# M0+ register map
Registers are 32-bit, read-write, reset 0x0 unless marked. A register's access mark holds for its fields unless they carry their own. Offsets are from the block's base; lines under a group give offsets from that group; [hi:lo] are bit positions; {n}, {i} and the like mark numbered series; 'fields as' and 'values as' point back to an identical list; <NAME> marks a mode.

## Memory map
0xE000E010 STK size 0x11 — SysTick timer
0xE000E100 NVIC size 0x33D — Nested Vectored Interrupt Controller
0xE000ED00 SCB size 0x41 — System control block
0xE000ED90 MPU size 0x15 — Memory protection unit
0xE000EF34 FPU size 0xD — Floting point unit

## FPU — Floting point unit
Base 0xE000EF34
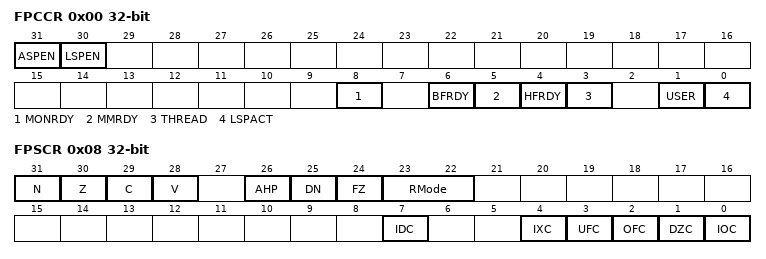
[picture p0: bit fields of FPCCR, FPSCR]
0x00 FPCCR — Floating-point context control register
  [31] ASPEN, [30] LSPEN, [8] MONRDY, [6] BFRDY, [5] MMRDY, [4] HFRDY, [3] THREAD, [1] USER, [0] LSPACT
0x04 FPCAR — Floating-point context address register
  [31:3] ADDRESS — Location of unpopulated floating-point
0x08 FPSCR — Floating-point status control register
  [31] N — Negative condition code flag
  [30] Z — Zero condition code flag
  [29] C — Carry condition code flag
  [28] V — Overflow condition code flag
  [26] AHP — Alternative half-precision control bit
  [25] DN — Default NaN mode control bit
  [24] FZ — Flush-to-zero mode control bit:
  [23:22] RMode — Rounding Mode control field
  [7] IDC — Input denormal cumulative exception bit.
  [4] IXC — Inexact cumulative exception bit
  [3] UFC — Underflow cumulative exception bit
  [2] OFC — Overflow cumulative exception bit
  [1] DZC — Division by zero cumulative exception bit.
  [0] IOC — Invalid operation cumulative exception bit

## MPU — Memory protection unit
Base 0xE000ED90
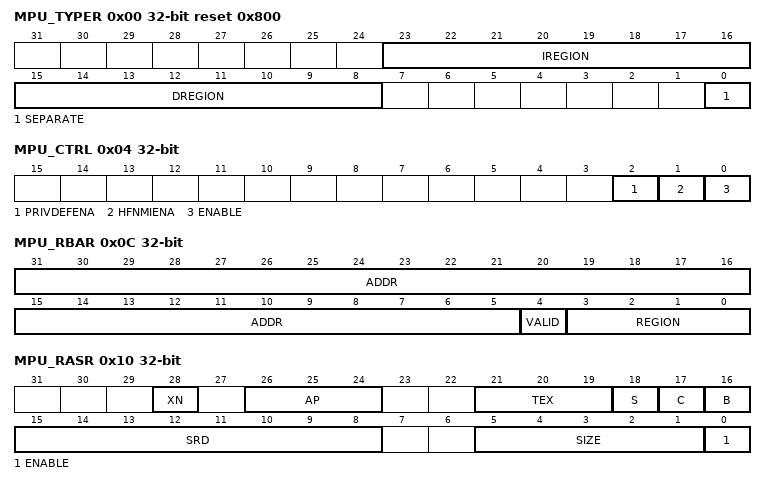
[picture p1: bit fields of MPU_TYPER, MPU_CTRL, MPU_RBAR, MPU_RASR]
0x00 MPU_TYPER ro reset 0x800 — MPU type register
  [23:16] IREGION — Number of MPU instruction regions
  [15:8] DREGION — Number of MPU data regions
  [0] SEPARATE — Separate flag
0x04 MPU_CTRL — MPU control register
  [2] PRIVDEFENA — Enable priviliged software access to default memory map
  [1] HFNMIENA — Enables the operation of MPU during hard fault
  [0] ENABLE — Enables the MPU
0x08 MPU_RNR — MPU region number register
  [7:0] REGION — MPU region
0x0C MPU_RBAR — MPU region base address register
  [31:5] ADDR — Region base address field
  [4] VALID — MPU region number valid
  [3:0] REGION — MPU region field
0x10 MPU_RASR — MPU region attribute and size register
  [28] XN — Instruction access disable bit
  [26:24] AP — Access permission
  [21:19] TEX — memory attribute
  [18] S — Shareable memory attribute
  [17] C — memory attribute
  [16] B — memory attribute
  [15:8] SRD — Subregion disable bits
  [5:1] SIZE — Size of the MPU protection region
  [0] ENABLE — Region enable bit.

## NVIC — Nested Vectored Interrupt Controller
Base 0xE000E100
0x00 ISER — Interrupt Set Enable Register
  [31:0] SETENA
0x80 ICER — Interrupt Clear Enable Register
  [31:0] CLRENA
0x100 ISPR — Interrupt Set-Pending Register
  [31:0] SETPEND
0x180 ICPR — Interrupt Clear-Pending Register
  [31:0] CLRPEND
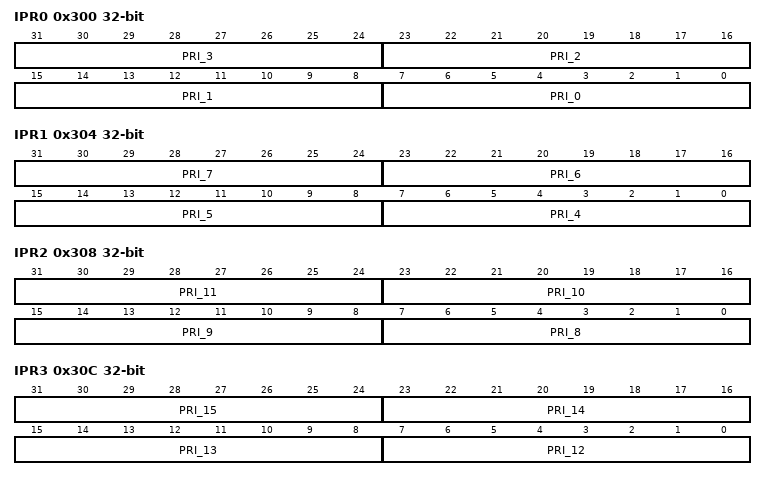
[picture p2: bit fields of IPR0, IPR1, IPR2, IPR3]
0x300 IPR0 — Interrupt Priority Register 0
  [8n+7:8n] PRI_{n} (n=0..3) — priority for interrupt {n}
0x304 IPR1 — Interrupt Priority Register 1
  [8n-25:8n-32] PRI_{n} (n=4..7) — priority for interrupt n
0x308 IPR2 — Interrupt Priority Register 2
  [8n-57:8n-64] PRI_{n} (n=8..11) — priority for interrupt n
0x30C IPR3 — Interrupt Priority Register 3
  [8n-89:8n-96] PRI_{n} (n=12..15) — priority for interrupt n
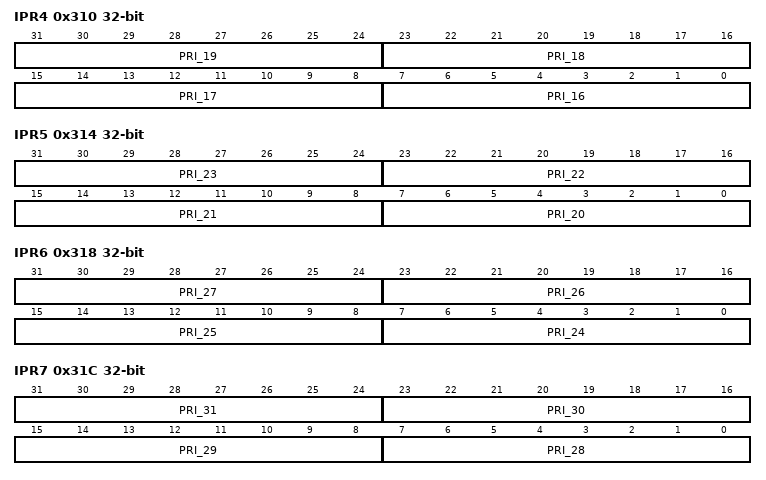
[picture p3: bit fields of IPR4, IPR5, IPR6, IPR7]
0x310 IPR4 — Interrupt Priority Register 4
  [8n-121:8n-128] PRI_{n} (n=16..19) — priority for interrupt n
0x314 IPR5 — Interrupt Priority Register 5
  [8n-153:8n-160] PRI_{n} (n=20..23) — priority for interrupt n
0x318 IPR6 — Interrupt Priority Register 6
  [8n-185:8n-192] PRI_{n} (n=24..27) — priority for interrupt n
0x31C IPR7 — Interrupt Priority Register 7
  [8n-217:8n-224] PRI_{n} (n=28..31) — priority for interrupt n
0x320 IPR8 — Interrupt Priority Register 8

## SCB — System control block
Base 0xE000ED00
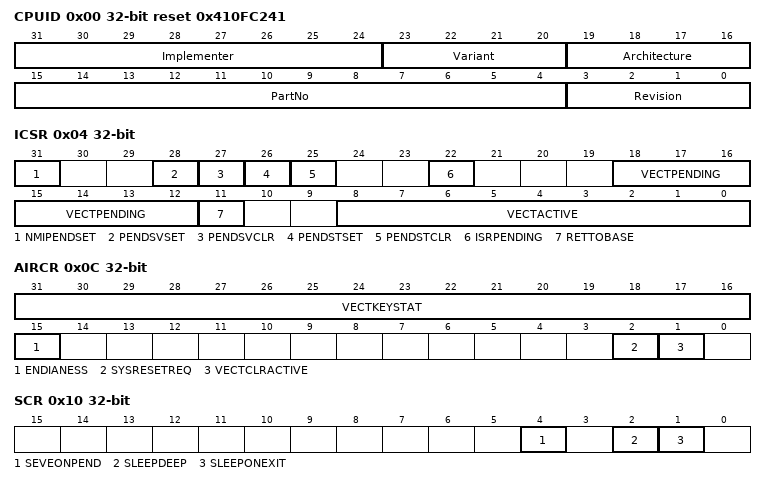
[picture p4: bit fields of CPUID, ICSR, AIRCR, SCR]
0x00 CPUID ro reset 0x410FC241 — CPUID base register
  [31:24] Implementer — Implementer code
  [23:20] Variant — Variant number
  [19:16] Architecture — Reads as 0xF
  [15:4] PartNo — Part number of the processor
  [3:0] Revision — Revision number
0x04 ICSR — Interrupt control and state register
  [31] NMIPENDSET — NMI set-pending bit.
  [28] PENDSVSET — PendSV set-pending bit
  [27] PENDSVCLR — PendSV clear-pending bit
  [26] PENDSTSET — SysTick exception set-pending bit
  [25] PENDSTCLR — SysTick exception clear-pending bit
  [22] ISRPENDING — Interrupt pending flag
  [18:12] VECTPENDING — Pending vector
  [11] RETTOBASE — Return to base level
  [8:0] VECTACTIVE — Active vector
0x08 VTOR — Vector table offset register
  [31:7] TBLOFF — Vector table base offset field
0x0C AIRCR — Application interrupt and reset control register
  [31:16] VECTKEYSTAT — Register key
  [15] ENDIANESS
  [2] SYSRESETREQ
  [1] VECTCLRACTIVE
0x10 SCR — System control register
  [4] SEVEONPEND — Send Event on Pending bit
  [2] SLEEPDEEP
  [1] SLEEPONEXIT
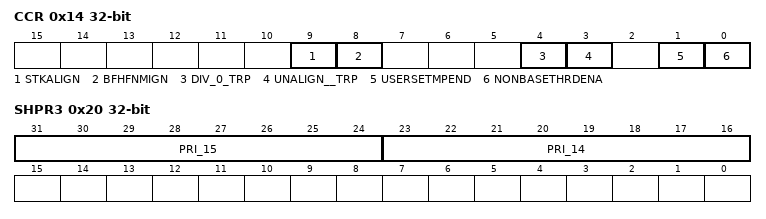
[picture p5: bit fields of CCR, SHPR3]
0x14 CCR — Configuration and control register
  [9] STKALIGN
  [8] BFHFNMIGN
  [4] DIV_0_TRP
  [3] UNALIGN__TRP
  [1] USERSETMPEND
  [0] NONBASETHRDENA — Configures how the processor enters Thread mode
0x1C SHPR2 — System handler priority registers
  [31:24] PRI_11 — Priority of system handler 11
0x20 SHPR3 — System handler priority registers
  [31:24] PRI_15 — Priority of system handler 15
  [23:16] PRI_14 — Priority of system handler 14

## STK — SysTick timer
Base 0xE000E010
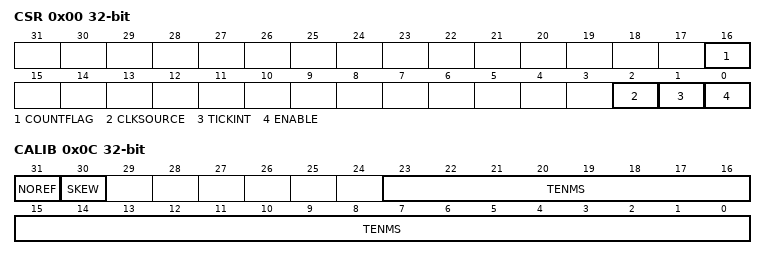
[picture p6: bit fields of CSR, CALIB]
0x00 CSR — SysTick control and status register
  [16] COUNTFLAG
  [2] CLKSOURCE — Clock source selection
  [1] TICKINT — SysTick exception request enable
  [0] ENABLE — Counter enable
0x04 RVR — SysTick reload value register
  [23:0] RELOAD — RELOAD value
0x08 CVR — SysTick current value register
  [23:0] CURRENT — Current counter value
0x0C CALIB — SysTick calibration value register
  [31] NOREF — NOREF flag. Reads as zero
  [30] SKEW — SKEW flag: Indicates whether the TENMS value is exact
  [23:0] TENMS — Calibration value
